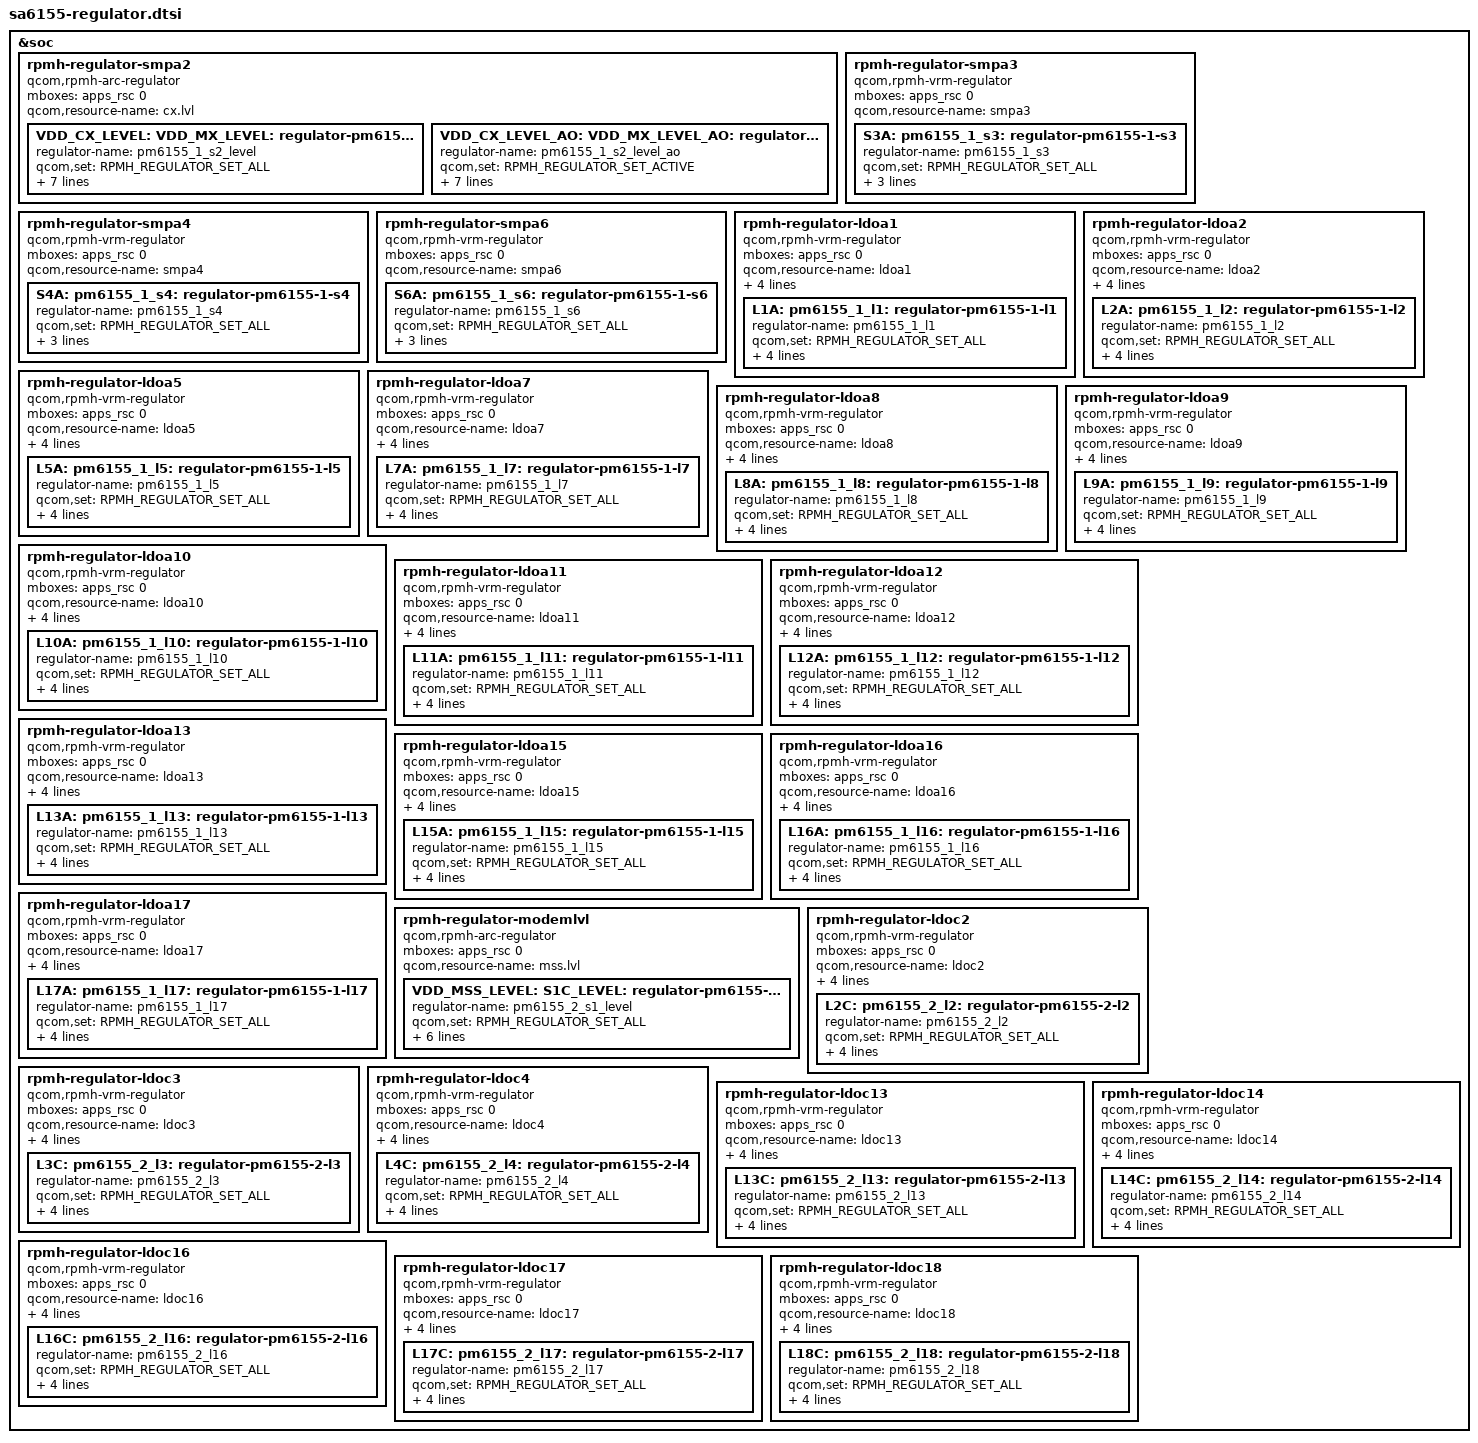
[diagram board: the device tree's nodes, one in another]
/* Copyright (c) 2018, The Linux Foundation. All rights reserved.
 *
 * This program is free software; you can redistribute it and/or modify
 * it under the terms of the GNU General Public License version 2 and
 * only version 2 as published by the Free Software Foundation.
 *
 * This program is distributed in the hope that it will be useful,
 * but WITHOUT ANY WARRANTY; without even the implied warranty of
 * MERCHANTABILITY or FITNESS FOR A PARTICULAR PURPOSE.  See the
 * GNU General Public License for more details.
 */

#include <dt-bindings/regulator/qcom,rpmh-regulator.h>

&soc {
	rpmh-regulator-smpa2 {
		compatible = "qcom,rpmh-arc-regulator";
		mboxes = <&apps_rsc 0>;
		qcom,resource-name = "cx.lvl";

		VDD_CX_LEVEL: VDD_MX_LEVEL:
		S2A_LEVEL:  pm6155_1_s2_level: regulator-pm6155-1-s2-level {
			regulator-name = "pm6155_1_s2_level";
			qcom,set = <RPMH_REGULATOR_SET_ALL>;
			regulator-min-microvolt
				= <RPMH_REGULATOR_LEVEL_RETENTION>;
			regulator-max-microvolt
				= <RPMH_REGULATOR_LEVEL_MAX>;
			qcom,init-voltage-level
				= <RPMH_REGULATOR_LEVEL_RETENTION>;
			qcom,min-dropout-voltage-level = <(-1)>;
		};

		VDD_CX_LEVEL_AO: VDD_MX_LEVEL_AO: S2A_LEVEL_AO:
		pm6155_1_s2_level_ao: regulator-pm6155-1-s2-level-ao {
			regulator-name = "pm6155_1_s2_level_ao";
			qcom,set = <RPMH_REGULATOR_SET_ACTIVE>;
			regulator-min-microvolt
				= <RPMH_REGULATOR_LEVEL_RETENTION>;
			regulator-max-microvolt
				= <RPMH_REGULATOR_LEVEL_MAX>;
			qcom,init-voltage-level
				= <RPMH_REGULATOR_LEVEL_RETENTION>;
			qcom,min-dropout-voltage-level = <(-1)>;
		};
	};

	rpmh-regulator-smpa3 {
		compatible = "qcom,rpmh-vrm-regulator";
		mboxes = <&apps_rsc 0>;
		qcom,resource-name = "smpa3";
		S3A: pm6155_1_s3: regulator-pm6155-1-s3 {
			regulator-name = "pm6155_1_s3";
			qcom,set = <RPMH_REGULATOR_SET_ALL>;
			regulator-min-microvolt = <600000>;
			regulator-max-microvolt = <650000>;
			qcom,init-voltage = <600000>;
		};
	};

	rpmh-regulator-smpa4 {
		compatible = "qcom,rpmh-vrm-regulator";
		mboxes = <&apps_rsc 0>;
		qcom,resource-name = "smpa4";
		S4A: pm6155_1_s4: regulator-pm6155-1-s4 {
			regulator-name = "pm6155_1_s4";
			qcom,set = <RPMH_REGULATOR_SET_ALL>;
			regulator-min-microvolt = <1800000>;
			regulator-max-microvolt = <1829000>;
			qcom,init-voltage = <1800000>;
		};
	};

	rpmh-regulator-smpa6 {
		compatible = "qcom,rpmh-vrm-regulator";
		mboxes = <&apps_rsc 0>;
		qcom,resource-name = "smpa6";
		S6A: pm6155_1_s6: regulator-pm6155-1-s6 {
			regulator-name = "pm6155_1_s6";
			qcom,set = <RPMH_REGULATOR_SET_ALL>;
			regulator-min-microvolt = <947000>;
			regulator-max-microvolt = <1404000>;
			qcom,init-voltage = <947000>;
		};
	};

	rpmh-regulator-ldoa1 {
		compatible = "qcom,rpmh-vrm-regulator";
		mboxes = <&apps_rsc 0>;
		qcom,resource-name = "ldoa1";
		qcom,regulator-type = "pmic5-ldo";
		qcom,supported-modes =
			<RPMH_REGULATOR_MODE_LPM
			 RPMH_REGULATOR_MODE_HPM>;
		qcom,mode-threshold-currents = <0 1>;
		L1A: pm6155_1_l1: regulator-pm6155-1-l1 {
			regulator-name = "pm6155_1_l1";
			qcom,set = <RPMH_REGULATOR_SET_ALL>;
			regulator-min-microvolt = <488000>;
			regulator-max-microvolt = <852000>;
			qcom,init-voltage = <488000>;
			qcom,init-mode = <RPMH_REGULATOR_MODE_LPM>;
		};
	};

	rpmh-regulator-ldoa2 {
		compatible = "qcom,rpmh-vrm-regulator";
		mboxes = <&apps_rsc 0>;
		qcom,resource-name = "ldoa2";
		qcom,regulator-type = "pmic5-ldo";
		qcom,supported-modes =
			<RPMH_REGULATOR_MODE_LPM
			 RPMH_REGULATOR_MODE_HPM>;
		qcom,mode-threshold-currents = <0 1>;
		L2A: pm6155_1_l2: regulator-pm6155-1-l2 {
			regulator-name = "pm6155_1_l2";
			qcom,set = <RPMH_REGULATOR_SET_ALL>;
			regulator-min-microvolt = <1650000>;
			regulator-max-microvolt = <3100000>;
			qcom,init-voltage = <1650000>;
			qcom,init-mode = <RPMH_REGULATOR_MODE_LPM>;
		};
	};

	rpmh-regulator-ldoa5 {
		compatible = "qcom,rpmh-vrm-regulator";
		mboxes = <&apps_rsc 0>;
		qcom,resource-name = "ldoa5";
		qcom,regulator-type = "pmic5-ldo";
		qcom,supported-modes =
			<RPMH_REGULATOR_MODE_LPM
			 RPMH_REGULATOR_MODE_HPM>;
		qcom,mode-threshold-currents = <0 1>;
		L5A: pm6155_1_l5: regulator-pm6155-1-l5 {
			regulator-name = "pm6155_1_l5";
			qcom,set = <RPMH_REGULATOR_SET_ALL>;
			regulator-min-microvolt = <875000>;
			regulator-max-microvolt = <975000>;
			qcom,init-voltage = <875000>;
			qcom,init-mode = <RPMH_REGULATOR_MODE_LPM>;
		};
	};

	rpmh-regulator-ldoa7 {
		compatible = "qcom,rpmh-vrm-regulator";
		mboxes = <&apps_rsc 0>;
		qcom,resource-name = "ldoa7";
		qcom,regulator-type = "pmic5-ldo";
		qcom,supported-modes =
			<RPMH_REGULATOR_MODE_LPM
			 RPMH_REGULATOR_MODE_HPM>;
		qcom,mode-threshold-currents = <0 1>;
		L7A: pm6155_1_l7: regulator-pm6155-1-l7 {
			regulator-name = "pm6155_1_l7";
			qcom,set = <RPMH_REGULATOR_SET_ALL>;
			regulator-min-microvolt = <1800000>;
			regulator-max-microvolt = <1900000>;
			qcom,init-voltage = <1800000>;
			qcom,init-mode = <RPMH_REGULATOR_MODE_LPM>;
		};
	};

	rpmh-regulator-ldoa8 {
		compatible = "qcom,rpmh-vrm-regulator";
		mboxes = <&apps_rsc 0>;
		qcom,resource-name = "ldoa8";
		qcom,regulator-type = "pmic5-ldo";
		qcom,supported-modes =
			<RPMH_REGULATOR_MODE_LPM
			 RPMH_REGULATOR_MODE_HPM>;
		qcom,mode-threshold-currents = <0 1>;
		L8A: pm6155_1_l8: regulator-pm6155-1-l8 {
			regulator-name = "pm6155_1_l8";
			qcom,set = <RPMH_REGULATOR_SET_ALL>;
			regulator-min-microvolt = <1150000>;
			regulator-max-microvolt = <1350000>;
			qcom,init-voltage = <1150000>;
			qcom,init-mode = <RPMH_REGULATOR_MODE_LPM>;
		};
	};

	rpmh-regulator-ldoa9 {
		compatible = "qcom,rpmh-vrm-regulator";
		mboxes = <&apps_rsc 0>;
		qcom,resource-name = "ldoa9";
		qcom,regulator-type = "pmic5-ldo";
		qcom,supported-modes =
			<RPMH_REGULATOR_MODE_LPM
			 RPMH_REGULATOR_MODE_HPM>;
		qcom,mode-threshold-currents = <0 1>;
		L9A: pm6155_1_l9: regulator-pm6155-1-l9 {
			regulator-name = "pm6155_1_l9";
			qcom,set = <RPMH_REGULATOR_SET_ALL>;
			regulator-min-microvolt = <1232000>;
			regulator-max-microvolt = <1232000>;
			qcom,init-voltage = <1232000>;
			qcom,init-mode = <RPMH_REGULATOR_MODE_LPM>;
		};
	};

	rpmh-regulator-ldoa10 {
		compatible = "qcom,rpmh-vrm-regulator";
		mboxes = <&apps_rsc 0>;
		qcom,resource-name = "ldoa10";
		qcom,regulator-type = "pmic5-ldo";
		qcom,supported-modes =
			<RPMH_REGULATOR_MODE_LPM
			 RPMH_REGULATOR_MODE_HPM>;
		qcom,mode-threshold-currents = <0 1>;
		L10A: pm6155_1_l10: regulator-pm6155-1-l10 {
			regulator-name = "pm6155_1_l10";
			qcom,set = <RPMH_REGULATOR_SET_ALL>;
			regulator-min-microvolt = <2950000>;
			regulator-max-microvolt = <3312000>;
			qcom,init-voltage = <2950000>;
			qcom,init-mode = <RPMH_REGULATOR_MODE_LPM>;
		};
	};

	rpmh-regulator-ldoa11 {
		compatible = "qcom,rpmh-vrm-regulator";
		mboxes = <&apps_rsc 0>;
		qcom,resource-name = "ldoa11";
		qcom,regulator-type = "pmic5-ldo";
		qcom,supported-modes =
			<RPMH_REGULATOR_MODE_LPM
			 RPMH_REGULATOR_MODE_HPM>;
		qcom,mode-threshold-currents = <0 1>;
		L11A: pm6155_1_l11: regulator-pm6155-1-l11 {
			regulator-name = "pm6155_1_l11";
			qcom,set = <RPMH_REGULATOR_SET_ALL>;
			regulator-min-microvolt = <1232000>;
			regulator-max-microvolt = <1260000>;
			qcom,init-voltage = <1232000>;
			qcom,init-mode = <RPMH_REGULATOR_MODE_LPM>;
		};
	};

	rpmh-regulator-ldoa12 {
		compatible = "qcom,rpmh-vrm-regulator";
		mboxes = <&apps_rsc 0>;
		qcom,resource-name = "ldoa12";
		qcom,regulator-type = "pmic5-ldo";
		qcom,supported-modes =
			<RPMH_REGULATOR_MODE_LPM
			 RPMH_REGULATOR_MODE_HPM>;
		qcom,mode-threshold-currents = <0 1>;
		L12A: pm6155_1_l12: regulator-pm6155-1-l12 {
			regulator-name = "pm6155_1_l12";
			qcom,set = <RPMH_REGULATOR_SET_ALL>;
			regulator-min-microvolt = <1800000>;
			regulator-max-microvolt = <1890000>;
			qcom,init-voltage = <1800000>;
			qcom,init-mode = <RPMH_REGULATOR_MODE_LPM>;
		};
	};

	rpmh-regulator-ldoa13 {
		compatible = "qcom,rpmh-vrm-regulator";
		mboxes = <&apps_rsc 0>;
		qcom,resource-name = "ldoa13";
		qcom,regulator-type = "pmic5-ldo";
		qcom,supported-modes =
			<RPMH_REGULATOR_MODE_LPM
			 RPMH_REGULATOR_MODE_HPM>;
		qcom,mode-threshold-currents = <0 1>;
		L13A: pm6155_1_l13: regulator-pm6155-1-l13 {
			regulator-name = "pm6155_1_l13";
			qcom,set = <RPMH_REGULATOR_SET_ALL>;
			regulator-min-microvolt = <3000000>;
			regulator-max-microvolt = <3230000>;
			qcom,init-voltage = <3000000>;
			qcom,init-mode = <RPMH_REGULATOR_MODE_LPM>;
		};
	};

	rpmh-regulator-ldoa15 {
		compatible = "qcom,rpmh-vrm-regulator";
		mboxes = <&apps_rsc 0>;
		qcom,resource-name = "ldoa15";
		qcom,regulator-type = "pmic5-ldo";
		qcom,supported-modes =
			<RPMH_REGULATOR_MODE_LPM
			 RPMH_REGULATOR_MODE_HPM>;
		qcom,mode-threshold-currents = <0 1>;
		L15A: pm6155_1_l15: regulator-pm6155-1-l15 {
			regulator-name = "pm6155_1_l15";
			qcom,set = <RPMH_REGULATOR_SET_ALL>;
			regulator-min-microvolt = <1904000>;
			regulator-max-microvolt = <1904000>;
			qcom,init-voltage = <1904000>;
			qcom,init-mode = <RPMH_REGULATOR_MODE_LPM>;
		};
	};

	rpmh-regulator-ldoa16 {
		compatible = "qcom,rpmh-vrm-regulator";
		mboxes = <&apps_rsc 0>;
		qcom,resource-name = "ldoa16";
		qcom,regulator-type = "pmic5-ldo";
		qcom,supported-modes =
			<RPMH_REGULATOR_MODE_LPM
			 RPMH_REGULATOR_MODE_HPM>;
		qcom,mode-threshold-currents = <0 1>;
		L16A: pm6155_1_l16: regulator-pm6155-1-l16 {
			regulator-name = "pm6155_1_l16";
			qcom,set = <RPMH_REGULATOR_SET_ALL>;
			regulator-min-microvolt = <3000000>;
			regulator-max-microvolt = <3312000>;
			qcom,init-voltage = <3000000>;
			qcom,init-mode = <RPMH_REGULATOR_MODE_LPM>;
		};
	};

	rpmh-regulator-ldoa17 {
		compatible = "qcom,rpmh-vrm-regulator";
		mboxes = <&apps_rsc 0>;
		qcom,resource-name = "ldoa17";
		qcom,regulator-type = "pmic5-ldo";
		qcom,supported-modes =
			<RPMH_REGULATOR_MODE_LPM
			 RPMH_REGULATOR_MODE_HPM>;
		qcom,mode-threshold-currents = <0 1>;
		L17A: pm6155_1_l17: regulator-pm6155-1-l17 {
			regulator-name = "pm6155_1_l17";
			qcom,set = <RPMH_REGULATOR_SET_ALL>;
			regulator-min-microvolt = <2950000>;
			regulator-max-microvolt = <3312000>;
			qcom,init-voltage = <3000000>;
			qcom,init-mode = <RPMH_REGULATOR_MODE_LPM>;
		};
	};

	/*  PM6155 S1 - VDD_MSS supply */
	rpmh-regulator-modemlvl {
		compatible = "qcom,rpmh-arc-regulator";
		mboxes = <&apps_rsc 0>;
		qcom,resource-name = "mss.lvl";

		VDD_MSS_LEVEL:
		S1C_LEVEL: pm6155_2_s1_level: regulator-pm6155-2-s1-level {
			regulator-name = "pm6155_2_s1_level";
			qcom,set = <RPMH_REGULATOR_SET_ALL>;
			regulator-min-microvolt =
					<RPMH_REGULATOR_LEVEL_RETENTION>;
			regulator-max-microvolt =
					<RPMH_REGULATOR_LEVEL_MAX>;
			qcom,init-voltage-level =
					<RPMH_REGULATOR_LEVEL_RETENTION>;
		};
	};

	rpmh-regulator-ldoc2 {
		compatible = "qcom,rpmh-vrm-regulator";
		mboxes = <&apps_rsc 0>;
		qcom,resource-name = "ldoc2";
		qcom,regulator-type = "pmic5-ldo";
		qcom,supported-modes =
			<RPMH_REGULATOR_MODE_LPM
			 RPMH_REGULATOR_MODE_HPM>;
		qcom,mode-threshold-currents = <0 1>;
		L2C: pm6155_2_l2: regulator-pm6155-2-l2 {
			regulator-name = "pm6155_2_l2";
			qcom,set = <RPMH_REGULATOR_SET_ALL>;
			regulator-min-microvolt = <2430000>;
			regulator-max-microvolt = <2970000>;
			qcom,init-voltage = <2430000>;
			qcom,init-mode = <RPMH_REGULATOR_MODE_LPM>;
		};
	};

	rpmh-regulator-ldoc3 {
		compatible = "qcom,rpmh-vrm-regulator";
		mboxes = <&apps_rsc 0>;
		qcom,resource-name = "ldoc3";
		qcom,regulator-type = "pmic5-ldo";
		qcom,supported-modes =
			<RPMH_REGULATOR_MODE_LPM
			 RPMH_REGULATOR_MODE_HPM>;
		qcom,mode-threshold-currents = <0 1>;
		L3C: pm6155_2_l3: regulator-pm6155-2-l3 {
			regulator-name = "pm6155_2_l3";
			qcom,set = <RPMH_REGULATOR_SET_ALL>;
			regulator-min-microvolt = <1200000>;
			regulator-max-microvolt = <1252000>;
			qcom,init-voltage = <1200000>;
			qcom,init-mode = <RPMH_REGULATOR_MODE_LPM>;
		};
	};

	rpmh-regulator-ldoc4 {
		compatible = "qcom,rpmh-vrm-regulator";
		mboxes = <&apps_rsc 0>;
		qcom,resource-name = "ldoc4";
		qcom,regulator-type = "pmic5-ldo";
		qcom,supported-modes =
			<RPMH_REGULATOR_MODE_LPM
			 RPMH_REGULATOR_MODE_HPM>;
		qcom,mode-threshold-currents = <0 1>;
		L4C: pm6155_2_l4: regulator-pm6155-2-l4 {
			regulator-name = "pm6155_2_l4";
			qcom,set = <RPMH_REGULATOR_SET_ALL>;
			regulator-min-microvolt = <1200000>;
			regulator-max-microvolt = <1252000>;
			qcom,init-voltage = <1200000>;
			qcom,init-mode = <RPMH_REGULATOR_MODE_LPM>;
		};
	};

	rpmh-regulator-ldoc13 {
		compatible = "qcom,rpmh-vrm-regulator";
		mboxes = <&apps_rsc 0>;
		qcom,resource-name = "ldoc13";
		qcom,regulator-type = "pmic5-ldo";
		qcom,supported-modes =
			<RPMH_REGULATOR_MODE_LPM
			 RPMH_REGULATOR_MODE_HPM>;
		qcom,mode-threshold-currents = <0 1>;
		L13C: pm6155_2_l13: regulator-pm6155-2-l13 {
			regulator-name = "pm6155_2_l13";
			qcom,set = <RPMH_REGULATOR_SET_ALL>;
			regulator-min-microvolt = <1650000>;
			regulator-max-microvolt = <2950000>;
			qcom,init-voltage = <1650000>;
			qcom,init-mode = <RPMH_REGULATOR_MODE_LPM>;
		};
	};

	rpmh-regulator-ldoc14 {
		compatible = "qcom,rpmh-vrm-regulator";
		mboxes = <&apps_rsc 0>;
		qcom,resource-name = "ldoc14";
		qcom,regulator-type = "pmic5-ldo";
		qcom,supported-modes =
			<RPMH_REGULATOR_MODE_LPM
			 RPMH_REGULATOR_MODE_HPM>;
		qcom,mode-threshold-currents = <0 1>;
		L14C: pm6155_2_l14: regulator-pm6155-2-l14 {
			regulator-name = "pm6155_2_l14";
			qcom,set = <RPMH_REGULATOR_SET_ALL>;
			regulator-min-microvolt = <1800000>;
			regulator-max-microvolt = <1850000>;
			qcom,init-voltage = <1800000>;
			qcom,init-mode = <RPMH_REGULATOR_MODE_LPM>;
		};
	};

	rpmh-regulator-ldoc16 {
		compatible = "qcom,rpmh-vrm-regulator";
		mboxes = <&apps_rsc 0>;
		qcom,resource-name = "ldoc16";
		qcom,regulator-type = "pmic5-ldo";
		qcom,supported-modes =
			<RPMH_REGULATOR_MODE_LPM
			 RPMH_REGULATOR_MODE_HPM>;
		qcom,mode-threshold-currents = <0 1>;
		L16C: pm6155_2_l16: regulator-pm6155-2-l16 {
			regulator-name = "pm6155_2_l16";
			qcom,set = <RPMH_REGULATOR_SET_ALL>;
			regulator-min-microvolt = <1650000>;
			regulator-max-microvolt = <2950000>;
			qcom,init-voltage = <1650000>;
			qcom,init-mode = <RPMH_REGULATOR_MODE_LPM>;
		};
	};

	rpmh-regulator-ldoc17 {
		compatible = "qcom,rpmh-vrm-regulator";
		mboxes = <&apps_rsc 0>;
		qcom,resource-name = "ldoc17";
		qcom,regulator-type = "pmic5-ldo";
		qcom,supported-modes =
			<RPMH_REGULATOR_MODE_LPM
			 RPMH_REGULATOR_MODE_HPM>;
		qcom,mode-threshold-currents = <0 1>;
		L17C: pm6155_2_l17: regulator-pm6155-2-l17 {
			regulator-name = "pm6155_2_l17";
			qcom,set = <RPMH_REGULATOR_SET_ALL>;
			regulator-min-microvolt = <1650000>;
			regulator-max-microvolt = <2950000>;
			qcom,init-voltage = <1650000>;
			qcom,init-mode = <RPMH_REGULATOR_MODE_LPM>;
		};
	};

	rpmh-regulator-ldoc18 {
		compatible = "qcom,rpmh-vrm-regulator";
		mboxes = <&apps_rsc 0>;
		qcom,resource-name = "ldoc18";
		qcom,regulator-type = "pmic5-ldo";
		qcom,supported-modes =
			<RPMH_REGULATOR_MODE_LPM
			 RPMH_REGULATOR_MODE_HPM>;
		qcom,mode-threshold-currents = <0 1>;
		L18C: pm6155_2_l18: regulator-pm6155-2-l18 {
			regulator-name = "pm6155_2_l18";
			qcom,set = <RPMH_REGULATOR_SET_ALL>;
			regulator-min-microvolt = <1000000>;
			regulator-max-microvolt = <1050000>;
			qcom,init-voltage = <1000000>;
			qcom,init-mode = <RPMH_REGULATOR_MODE_LPM>;
		};
	};
};

